# VIMS register map
Vendor: Texas Instruments
Peripheral module from a debugger description file (folder CC26x0R2F).
Registers are 32-bit, read-only, reset 0x0 unless marked. A register's access mark holds for its fields unless they carry their own. Offsets are as the file gives them; lines under a group give offsets from that group; [hi:lo] are bit positions; {n}, {i} and the like mark numbered series; 'fields as' and 'values as' point back to an identical list; <NAME> marks a mode.

## VIMS — Versatile Instruction Memory System Controls memory access to the Flash and encapsulates the following instruction memories: - Boot ROM - Cache / GPRAM
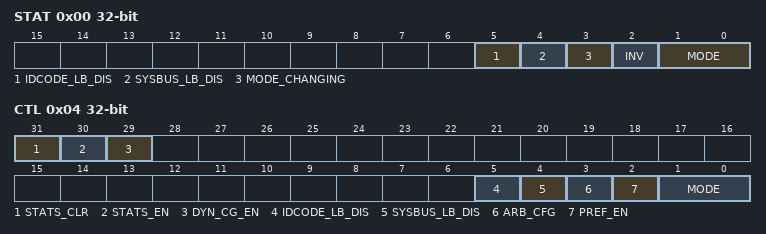
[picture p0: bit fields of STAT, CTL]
0x00 STAT — Status Displays current VIMS mode and line buffer status
  [5] IDCODE_LB_DIS — Icode/Dcode flash line buffer status 0: Enabled or in transition to disabled 1: Disabled and flushed
  [4] SYSBUS_LB_DIS — Sysbus flash line buffer control 0: Enabled or in transition to disabled 1: Disabled and flushed
  [3] MODE_CHANGING — VIMS mode change status 0: VIMS is in the mode defined by MODE 1: VIMS is in the process of changing to the mode given in CTL.MODE
  [2] INV — This bit is set when invalidation of the cache memory is active / ongoing
  [1:0] MODE — Current VIMS mode
    3=OFF (VIMS Off mode); 1=CACHE (VIMS Cache mode); 0=GPRAM (VIMS GPRAM mode)
0x04 CTL access per field — Control Configure VIMS mode and line buffer settings
  [31] STATS_CLR rw — Set this bit to clear statistic counters.
  [30] STATS_EN rw — Set this bit to enable statistic counters.
  [29] DYN_CG_EN rw — 0: The in-built clock gate functionality is bypassed. 1: The in-built clock gate functionality is enabled, automatically gating the clock when not needed.
  [5] IDCODE_LB_DIS rw — Icode/Dcode flash line buffer control 0: Enable 1: Disable
  [4] SYSBUS_LB_DIS rw — Sysbus flash line buffer control 0: Enable 1: Disable
  [3] ARB_CFG rw — Icode/Dcode and sysbus arbitation scheme 0: Static arbitration (icode/docde > sysbus) 1: Round-robin arbitration
  [2] PREF_EN rw — Tag prefetch control 0: Disabled 1: Enabled
  [1:0] MODE rw — VIMS mode request. Write accesses to this field will be blocked while STAT.MODE_CHANGING is set to 1. Note: Transaction from CACHE mode to GPRAM mode should be done through OFF mode to minimize flash block delay.
    values as STAT.MODE
